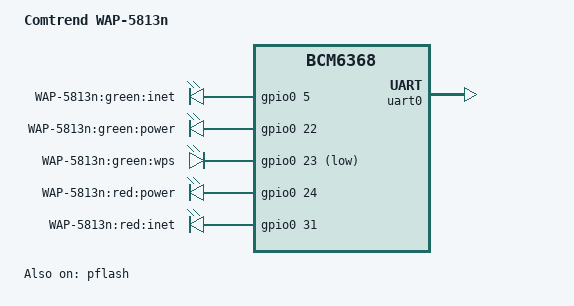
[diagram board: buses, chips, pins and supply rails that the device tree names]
/*
 * Copyright (C) 2017 Álvaro Fernández Rojas <noltari@gmail.com>
 *
 * SPDX-License-Identifier:	GPL-2.0+
 */

/dts-v1/;

#include "brcm,bcm6368.dtsi"

/ {
	model = "Comtrend WAP-5813n";
	compatible = "comtrend,wap-5813n", "brcm,bcm6368";

	aliases {
		serial0 = &uart0;
	};

	chosen {
		stdout-path = "serial0:115200n8";
	};

	gpio-leds {
		compatible = "gpio-leds";

		inet_green {
			label = "WAP-5813n:green:inet";
			gpios = <&gpio0 5 GPIO_ACTIVE_HIGH>;
		};

		power_green {
			label = "WAP-5813n:green:power";
			gpios = <&gpio0 22 GPIO_ACTIVE_HIGH>;
			default-state = "on";
		};

		wps_green {
			label = "WAP-5813n:green:wps";
			gpios = <&gpio0 23 GPIO_ACTIVE_LOW>;
		};

		power_red {
			label = "WAP-5813n:red:power";
			gpios = <&gpio0 24 GPIO_ACTIVE_HIGH>;
		};

		inet_red {
			label = "WAP-5813n:red:inet";
			gpios = <&gpio0 31 GPIO_ACTIVE_HIGH>;
		};
	};
};

&gpio0 {
	status = "okay";
};

&pflash {
	status = "okay";
};

&uart0 {
	u-boot,dm-pre-reloc;
	status = "okay";
};
